# ESP32S3_RADIO register map
File version: 0.1.0
Registers are 32-bit, read-write, no defined reset value unless marked. A register's access mark holds for its fields unless they carry their own. Offsets are from the block's base; [hi:lo] are bit positions.

## SENSITIVE — SRAM bank ownership
Base 0x600C1000
0x1C INTERNAL_SRAM_USAGE_3 — Hands SRAM banks to the dump engine The banks by field bit: | Bit | Bank | Use in esp_sdr | |---|---|---| | 0 | 0x3fcb0000, 64 KiB | ring (`CONFIG_ESP_SDR_RING`) | | 1 | 0x3fcc0000 | second DAC and capture bank (`CONFIG_ESP_SDR_BANK1`), ring | | 2 | 0x3fcd0000 | capture bank; the one `adctrig()` and `dactrig()` use | | 3 | 0x3fce0000 | never: it holds ROM data | The library saves the register and restores it after each use. Undocumented behaviour: - While the engine owns a bank the CPUs cannot reach any of it, so nothing else may live there; the linker snippets reserve the banks and lower `_heap_sentry`. - CPU stores reach the DAC only if made while the CPU owns the bank; otherwise the DAC replays the old content. - The engine follows a change of the field while it runs, in both directions: the ring splits one continuous capture into gapless units, the DAC switches banks mid-pass. - Bank 3 holds ROM data (0x3fceffxx); handing it to the engine wedges the board, USB and shell die. Evidence: `lib/esp_sdr/src/esp_sdr_rx.c:246-278`, `lib/esp_sdr/src/esp_sdr.c:123-133` (save and restore) Evidence: `lib/esp_sdr/esp_sdr_bank_s3.ld:4-34` (reserved banks) Evidence: *measured* `lib/esp_sdr/src/esp_sdr_tx.c:346-349` (CPU stores and the DAC) Evidence: *measured* hardware-quirks.md, "Capture and DAC engine"; `lib/esp_sdr/src/esp_sdr_priv.h:237-245` (a change while running) Evidence: *measured* bench 2026-10-05, `lib/esp_sdr/esp_sdr_bank_s3.ld:43-47`; *upstream* `modules/lib/esp-sdr/main/common/ring_capture.h:26` (bank 3)
  [3:0] INTERNAL_SRAM_MAC_DUMP_USAGE — One-hot: bit n hands bank n to the engine, for capture and playback alike; 0 gives every bank back to the CPUs. The HAL defines the field without a description. Evidence: `modules/hal/espressif/components/soc/esp32s3/register/soc/sensitive_reg.h:101-107`

## AGC — AGC force
Base 0x6001C000
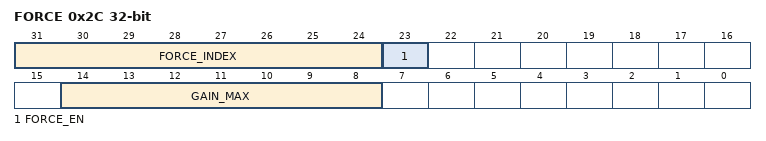
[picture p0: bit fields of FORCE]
0x2C FORCE — Forced receive gain index, force bit and largest calibrated index Upstream calls the register AGCPWR_CTRL7. The PHY's `rom_agc_reg_init()` pulses AGC_FORCE_EN (bit 23) with index 0x32. The ESP32-C6 has the same layout. Levels with a 50 ohm load: AGC -25.7, index 0 -46.0, 40 -39.0, 60 -27.0, 82 -19.9 dBFS. - `force_rx_gain(force, index, 0)` also calls `bt_rx_force(0)`, which clears AGC_R80_REG bits 7:6 and steps FE_R110_REG bits 9:8 through 2, 3 and 0. - A forced gain is occasionally lost; this register does not show it (hardware-quirks.md, "The forced receive gain gets lost"). - A new forced index alone can leave stale receive state, so a gain change reruns the front-end setup. Evidence: *decompile* S3 `phy_reg.o` (`rom_agc_reg_init()`) Evidence: *measured* bench 2026-10-05 (levels) Evidence: *decompile* S3 `phy_test.o` (`bt_rx_force(0)`) Evidence: *upstream* `modules/lib/esp-sdr/main/targets/esp32s3/receiver.c:107-113`; `lib/esp_sdr/src/esp_sdr_rx.c:164-166` (gain change)
  [31:24] FORCE_INDEX — Forced receive gain index. Evidence: *decompile* S3 `phy_test.o`; *working*
  [23] FORCE_EN — Force: 1 holds the index, 0 hands the gain to the AGC. Evidence: *decompile* S3 `phy_test.o`; *working*
  [14:8] GAIN_MAX — Largest calibrated gain index, 0 to 82, written by the PHY when it builds the gain table (capped at 82). Larger reads point at uncalibrated slots; the library treats them as 0. Evidence: *working* `lib/esp_sdr/src/esp_sdr_rx.c:29-34`; *decompile* S3 `phy_rx_gain.o`; *upstream* `modules/lib/esp-sdr/main/common/burst_gain.h:1-4, 29-37`
0x6C R6C — AGC RSSI; lead, not tried
  [15:8] RSSI ro — AGC RSSI. With the CCA busy counters (BB_CCA_BUSY_CNT0_REG to BB_CCA_BUSY_CNT2_REG) a candidate for 802.15.4 energy detection and CCA, work it could take off the CPU; lead, not tried. Evidence: *decompile* S3 `libphy.a`
0x80 R80 — Unknown; bits 7:6 cleared by `bt_rx_force(0)`
  [7:6] B7_6 — Cleared by `bt_rx_force(0)`, which `force_rx_gain(force, index, 0)` calls (see AGC_FORCE_REG). Evidence: *decompile* S3 `phy_test.o`
